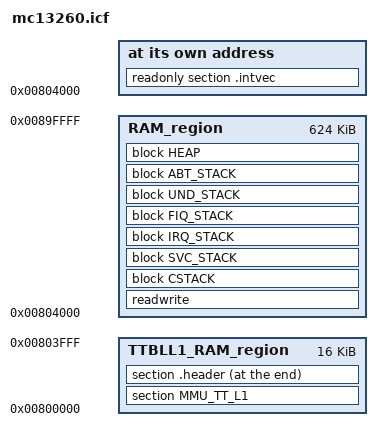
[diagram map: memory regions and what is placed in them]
/*###ICF### Section handled by ICF editor, don't touch! ****/
/*-Editor annotation file-*/
/* IcfEditorFile="$TOOLKIT_DIR$\config\ide\IcfEditor\a_v1_0.xml" */
/*-Specials-*/
define symbol __ICFEDIT_intvec_start__ = 0x00804000;
/*-Memory Regions-*/
define symbol __ICFEDIT_region_ROM_start__   = 0x0;
define symbol __ICFEDIT_region_ROM_end__     = 0x0;
define symbol __ICFEDIT_region_RAM_start__   = 0x00804000;
define symbol __ICFEDIT_region_RAM_end__     = 0x0089FFFF;
/*-Sizes-*/
define symbol __ICFEDIT_size_cstack__   = 0x1000;
define symbol __ICFEDIT_size_svcstack__ = 0x0;
define symbol __ICFEDIT_size_irqstack__ = 0x40;
define symbol __ICFEDIT_size_fiqstack__ = 0x0;
define symbol __ICFEDIT_size_undstack__ = 0x0;
define symbol __ICFEDIT_size_abtstack__ = 0x0;
define symbol __ICFEDIT_size_heap__     = 0x1000;
/**** End of ICF editor section. ###ICF###*/

define symbol __region_TTBLL1_RAM_start__   = 0x00800000;
define symbol __region_TTBLL1_RAM_end__     = 0x00803FFF;
define symbol __size_mixed_block__          = 0x4000;

define memory mem with size = 4G;
define region RAM_region   = mem:[from __ICFEDIT_region_RAM_start__   to __ICFEDIT_region_RAM_end__];
define region TTBLL1_RAM_region   = mem:[from __region_TTBLL1_RAM_start__   to __region_TTBLL1_RAM_end__];

define block CSTACK    with alignment = 8, size = __ICFEDIT_size_cstack__   { };
define block SVC_STACK with alignment = 8, size = __ICFEDIT_size_svcstack__ { };
define block IRQ_STACK with alignment = 8, size = __ICFEDIT_size_irqstack__ { };
define block FIQ_STACK with alignment = 8, size = __ICFEDIT_size_fiqstack__ { };
define block UND_STACK with alignment = 8, size = __ICFEDIT_size_undstack__ { };
define block ABT_STACK with alignment = 8, size = __ICFEDIT_size_abtstack__ { };
define block HEAP      with alignment = 8, size = __ICFEDIT_size_heap__     { };

initialize by copy { readwrite };
do not initialize  { section .noinit };

place in TTBLL1_RAM_region {section MMU_TT_L1};
place at end of TTBLL1_RAM_region {section .header};

place at address mem:__ICFEDIT_intvec_start__ { readonly section .intvec };

place in RAM_region   { block image with fixed order {readonly, section .image_end}};
place in RAM_region   { readwrite,
                        block CSTACK, block SVC_STACK, block IRQ_STACK, block FIQ_STACK,
                        block UND_STACK, block ABT_STACK, block HEAP };
                        
define exported symbol __intvec_start = __ICFEDIT_intvec_start__;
